AUTOSAR XML (schema 00044)
package /E40_Platform_System_SystemPackage/Components
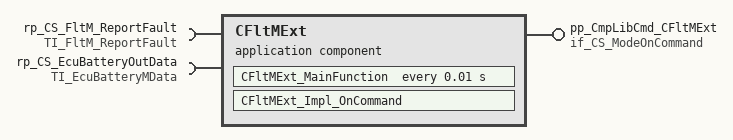
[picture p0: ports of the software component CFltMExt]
  application sw component type CFltMExt
    provide port pp_CmpLibCmd_CFltMExt: server-com-spec{operation=Impl_OnCommand, queue-length=1}, provided-interface=if_CS_ModeOnCommand
    require port rp_CS_FltM_ReportFault: client-com-spec=FltM_ReportFault, required-interface=TI_FltM_ReportFault
    require port rp_CS_EcuBatteryOutData: required-com-specs=[EcuBatteryM_GetChannelStatus, EcuBatteryM_GetDIOStatus], required-interface=TI_EcuBatteryMData
    behavior IB_CFltMExt
      operation invoked event OIE_pp_CmpLibCmd_CFltMExt_CFltMExt_Impl_OnCommandTrigByImpl_OnCommand: start-on-event=CFltMExt_Impl_OnCommand, operation=pp_CmpLibCmd_CFltMExt.Impl_OnCommand
      timing event TECFltMExt_MainFunction: start-on-event=CFltMExt_MainFunction, period=0.01
      port-api-options:
        enable-take-address=false, indirect-api=false, port=pp_CmpLibCmd_CFltMExt
        enable-take-address=false, indirect-api=false, port=rp_CS_FltM_ReportFault
        enable-take-address=false, indirect-api=false, port=rp_CS_EcuBatteryOutData
      runnable CFltMExt_Impl_OnCommand: can-be-invoked-concurrently=true
        sync call OA_rp_CS_FltM_ReportFault_FltM_ReportFault: operation=rp_CS_FltM_ReportFault.FltM_ReportFault
        sync call OA_rp_CS_EcuBatteryOutData_EcuBatteryM_GetChannelStatus: operation=rp_CS_EcuBatteryOutData.EcuBatteryM_GetChannelStatus
        sync call OA_rp_CS_EcuBatteryOutData_EcuBatteryM_GetDIOStatus: operation=rp_CS_EcuBatteryOutData.EcuBatteryM_GetDIOStatus
      runnable CFltMExt_MainFunction: can-be-invoked-concurrently=true
        sync call OA_rp_CS_FltM_ReportFault_FltM_ReportFault: operation=rp_CS_FltM_ReportFault.FltM_ReportFault
        sync call OA_rp_CS_EcuBatteryOutData_EcuBatteryM_GetChannelStatus: operation=rp_CS_EcuBatteryOutData.EcuBatteryM_GetChannelStatus
        sync call OA_rp_CS_EcuBatteryOutData_EcuBatteryM_GetDIOStatus: operation=rp_CS_EcuBatteryOutData.EcuBatteryM_GetDIOStatus
  swc implementation IMPL_CFltMExt: behavior=IB_CFltMExt
